VERSION ""

NS_ :

BS_:

BU_: Minieye ADAS
VAL_TABLE_ System_Status 3 "reserve" 2 "reserve" 1 "System fault" 0 "System normal" ;
VAL_TABLE_ Overspeed_Warn 1 "warning" 0 "no warning" ;
VAL_TABLE_ HWM_Warn 1 "warning" 0 "no warning" ;
VAL_TABLE_ FCW_Status 1 "warning" 0 "no warning" ;
VAL_TABLE_ LLDW_Warn 1 "warning" 0 "no warning" ;
VAL_TABLE_ RLDW_Warn 1 "warning" 0 "no warning" ;
VAL_TABLE_ TSR_Detect 2 "detect tsr discharge" 1 "detect tsr" 0 "no detect tsr" ;
VAL_TABLE_ CAR_Detect 1 "detect the front car" 0 "no detect" ;
VAL_TABLE_ Stop_Detect 1 "car stop" 0 "car run" ;
VAL_TABLE_ PED_Detect 1 "detect ped" 0 "no detect ped" ;
VAL_TABLE_ PCW_Warn 1 "Collision warning" 0 "no warning" ;
VAL_TABLE_ HMW_Detect 2 "danger distance" 1 "safe distance" 0 "no detect the car" ;
VAL_TABLE_ LDW_Status 1 "Open" 0 "Close" ;
VAL_TABLE_ Llane_Detect 2 "reserve" 1 "detect" 0 "no detect" ;
VAL_TABLE_ Rlane_Detect 2 "reserve" 1 "detect" 0 "no detect" ;
VAL_TABLE_ HMW_Detect_Warn 2 "reserve" 1 "warning" 0 "no warning" ;
VAL_TABLE_ FrontCar_Status 2 "reserve" 1 "Detect the front car" 0 "Not detect car" ;

BO_ 1 New_Message_6: 8 Vector__XXX
 SG_ New_Signal_23 : 15|8@1+ (1,0) [0|0] "" Vector__XXX

BO_ 0 New_Message_5: 8 Vector__XXX
 SG_ New_Signal_22 : 8|8@1+ (1,0) [0|0] "" Vector__XXX

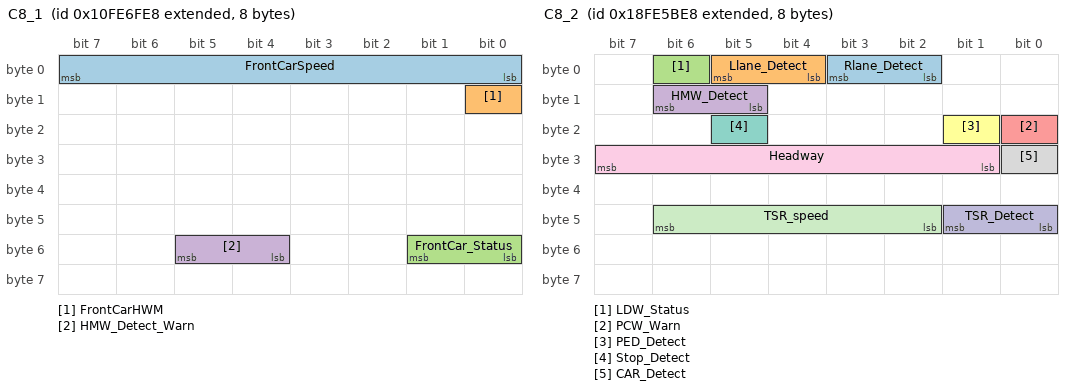
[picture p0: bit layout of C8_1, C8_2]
BO_ 2432593896 C8_1: 8 ADAS
 SG_ FrontCarSpeed : 0|8@1+ (1,0) [0|250] "" Vector__XXX
 SG_ FrontCarHWM : 8|1@1- (2,1) [0|250] "sec" Vector__XXX
 SG_ FrontCar_Status : 48|2@1+ (1,0) [0|3] "" Vector__XXX
 SG_ HMW_Detect_Warn : 52|2@1+ (1,0) [0|3] "2"  Minieye

BO_ 2566806504 C8_2: 8 Minieye
 SG_ Rlane_Detect : 2|2@1+ (1,0) [0|1] "" Vector__XXX
 SG_ Llane_Detect : 4|2@1+ (1,0) [0|1] "" Vector__XXX
 SG_ LDW_Status : 6|1@1+ (1,0) [0|1] "" Vector__XXX
 SG_ HMW_Detect : 13|2@1+ (1,0) [0|3] "" Vector__XXX
 SG_ PCW_Warn : 16|1@1+ (1,0) [0|1] "" Vector__XXX
 SG_ PED_Detect : 17|1@1+ (1,0) [0|1] "" Vector__XXX
 SG_ Stop_Detect : 21|1@1+ (1,0) [0|1] "" Vector__XXX
 SG_ CAR_Detect : 24|1@1+ (1,0) [0|1] "" Vector__XXX
 SG_ Headway : 25|7@1+ (0.1,0) [0|127] "s" Vector__XXX
 SG_ TSR_Detect : 40|2@1+ (1,0) [0|4] "s" Vector__XXX
 SG_ TSR_speed : 42|5@1+ (5,0) [0|120] "" Vector__XXX

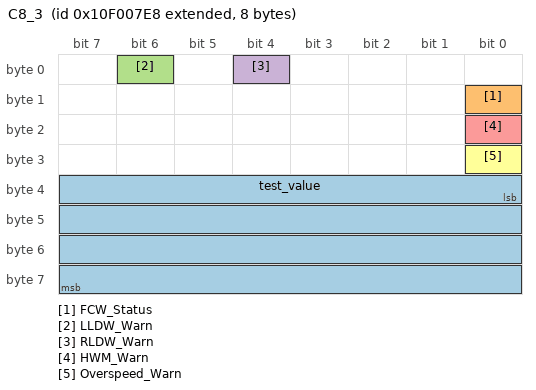
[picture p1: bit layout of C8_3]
BO_ 2431649768 C8_3: 8 Vector__XXX
 SG_ test_value : 32|32@1- (1,0) [-3.4E+038|3.4E+038] "sec" Vector__XXX
 SG_ FCW_Status : 8|1@1+ (1,0) [0|1] "" Vector__XXX
 SG_ LLDW_Warn : 6|1@1+ (1,0) [0|1] "" Vector__XXX
 SG_ RLDW_Warn : 4|1@1+ (1,0) [0|1] "" Vector__XXX
 SG_ HWM_Warn : 16|1@1+ (1,0) [0|1] "" Vector__XXX
 SG_ Overspeed_Warn : 24|1@1+ (1,0) [0|1] "" Vector__XXX

BO_ 419351272 C8_4: 8 Vector__XXX
 SG_ System_Status : 2|2@1+ (1,0) [0|3] "" Vector__XXX

CM_ SG_ 2431649768 test_value "just for test";
VAL_ 2432593896 FrontCar_Status 2 "reserve" 1 "Detect the front car" 0 "Not detect car" ;
VAL_ 2432593896 HMW_Detect_Warn 2 "reserve" 1 "warning" 0 "no warning" ;
VAL_ 2566806504 Rlane_Detect 2 "reserve" 1 "detect" 0 "no detect" ;
VAL_ 2566806504 Llane_Detect 2 "reserve" 1 "detect" 0 "no detect" ;
VAL_ 2566806504 LDW_Status 1 "Open" 0 "Close" ;
VAL_ 2566806504 HMW_Detect 2 "danger distance" 1 "safe distance" 0 "no detect the car" ;
VAL_ 2566806504 PCW_Warn 1 "Collision warning" 0 "no warning" ;
VAL_ 2566806504 PED_Detect 1 "detect ped" 0 "no detect ped" ;
VAL_ 2566806504 Stop_Detect 1 "car stop" 0 "car run" ;
VAL_ 2566806504 CAR_Detect 1 "detect the front car" 0 "no detect" ;
VAL_ 2566806504 TSR_Detect 2 "detect tsr discharge" 1 "detect tsr" 0 "no detect tsr" ;
VAL_ 2431649768 FCW_Status 1 "warning" 0 "no warning" ;
VAL_ 2431649768 LLDW_Warn 1 "warning" 0 "no warning" ;
VAL_ 2431649768 RLDW_Warn 1 "warning" 0 "no warning" ;
VAL_ 2431649768 HWM_Warn 1 "warning" 0 "no warning" ;
VAL_ 2431649768 Overspeed_Warn 1 "warning" 0 "no warning" ;
VAL_ 419351272 System_Status 3 "reserve" 2 "reserve" 1 "System fault" 0 "System normal" ;
SIG_VALTYPE_ 2431649768 test_value : 1;
